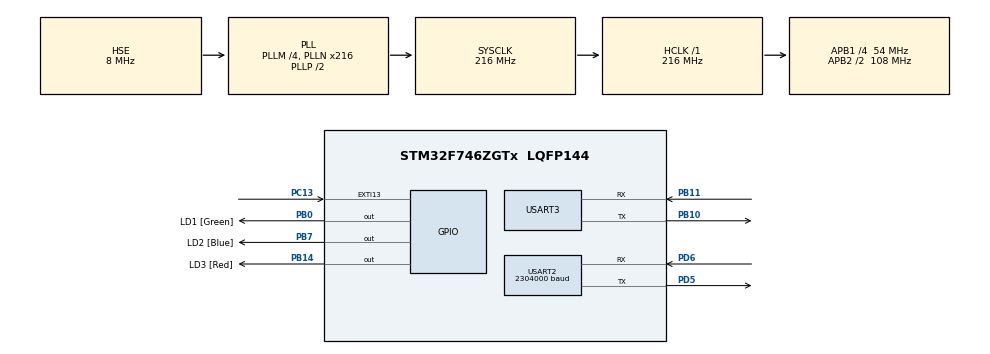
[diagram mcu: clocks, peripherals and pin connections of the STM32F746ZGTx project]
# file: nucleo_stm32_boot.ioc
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CORTEX_M7.ART_ACCLERATOR_ENABLE=1
CORTEX_M7.CPU_DCache=Enabled
CORTEX_M7.CPU_ICache=Enabled
CORTEX_M7.Enable-Cortex_Memory_Protection_Unit_Region0_Settings=MPU_REGION_ENABLE
CORTEX_M7.PREFETCH_ENABLE=1
CORTEX_M7.SubRegionDisable-Cortex_Memory_Protection_Unit_Region0_Settings=0x0
Dma.Request0=USART2_TX
Dma.Request1=USART2_RX
Dma.USART2_RX.1.Direction=DMA_PERIPH_TO_MEMORY
Dma.USART2_RX.1.FIFOMode=DMA_FIFOMODE_DISABLE
Dma.USART2_RX.1.Instance=DMA1_Stream5
Dma.USART2_RX.1.MemDataAlignment=DMA_MDATAALIGN_BYTE
Dma.USART2_RX.1.MemInc=DMA_MINC_ENABLE
Dma.USART2_RX.1.Mode=DMA_CIRCULAR
Dma.USART2_RX.1.PeriphDataAlignment=DMA_PDATAALIGN_BYTE
Dma.USART2_RX.1.PeriphInc=DMA_PINC_DISABLE
Dma.USART2_RX.1.Priority=DMA_PRIORITY_HIGH
Dma.USART2_TX.0.Direction=DMA_MEMORY_TO_PERIPH
Dma.USART2_TX.0.FIFOMode=DMA_FIFOMODE_ENABLE
Dma.USART2_TX.0.FIFOThreshold=DMA_FIFO_THRESHOLD_FULL
Dma.USART2_TX.0.Instance=DMA1_Stream6
Dma.USART2_TX.0.MemBurst=DMA_MBURST_SINGLE
Dma.USART2_TX.0.MemDataAlignment=DMA_MDATAALIGN_BYTE
Dma.USART2_TX.0.MemInc=DMA_MINC_ENABLE
Dma.USART2_TX.0.Mode=DMA_NORMAL
Dma.USART2_TX.0.PeriphBurst=DMA_PBURST_SINGLE
Dma.USART2_TX.0.PeriphDataAlignment=DMA_PDATAALIGN_BYTE
Dma.USART2_TX.0.PeriphInc=DMA_PINC_DISABLE
Dma.USART2_TX.0.Priority=DMA_PRIORITY_VERY_HIGH
Mcu.Family=STM32F7
Mcu.Name=STM32F746ZGTx
Mcu.Package=LQFP144
NVIC.DMA1_Stream5_IRQn=true\:0\:0\:false\:false\:true\:true\:true
NVIC.DMA1_Stream6_IRQn=true\:0\:0\:false\:false\:true\:true\:true
NVIC.EXTI15_10_IRQn=true\:0\:0\:false\:false\:true\:true\:true
NVIC.PriorityGroup=NVIC_PRIORITYGROUP_4
NVIC.USART2_IRQn=true\:0\:0\:false\:false\:true\:true\:true
PA13.GPIO_Label=TMS
PA13.Mode=Serial_Wire
PA13.Signal=SYS_JTMS-SWDIO
PA14.GPIO_Label=TCK
PA14.Mode=Serial_Wire
PA14.Signal=SYS_JTCK-SWCLK
PB0.GPIO_Label=LD1 [Green]
PB0.Signal=GPIO_Output
PB10.Mode=Asynchronous
PB10.Signal=USART3_TX
PB11.Mode=Asynchronous
PB11.Signal=USART3_RX
PB14.GPIO_Label=LD3 [Red]
PB14.Signal=GPIO_Output
PB7.GPIO_Label=LD2 [Blue]
PB7.Signal=GPIO_Output
PC13.Signal=GPXTI13
PC14/OSC32_IN.Mode=LSE-External-Clock-Source
PC14/OSC32_IN.Signal=RCC_OSC32_IN
PC15/OSC32_OUT.Mode=LSE-External-Clock-Source
PC15/OSC32_OUT.Signal=RCC_OSC32_OUT
PD5.Mode=Asynchronous
PD5.Signal=USART2_TX
PD6.GPIO_Speed=GPIO_SPEED_FREQ_VERY_HIGH
PD6.Mode=Asynchronous
PD6.Signal=USART2_RX
PH0/OSC_IN.GPIO_Label=MCO [STM32F103CBT6_PA8]
PH0/OSC_IN.Mode=HSE-External-Clock-Source
PH0/OSC_IN.Signal=RCC_OSC_IN
PH1/OSC_OUT.Mode=HSE-External-Clock-Source
PH1/OSC_OUT.Signal=RCC_OSC_OUT
ProjectManager.HeapSize=0x200
ProjectManager.StackSize=0x400
ProjectManager.TargetToolchain=SW4STM32
RCC.48MHZClocksFreq_Value=24000000
RCC.AHBFreq_Value=216000000
RCC.APB1CLKDivider=RCC_HCLK_DIV4
RCC.APB1Freq_Value=54000000
RCC.APB1TimFreq_Value=108000000
RCC.APB2CLKDivider=RCC_HCLK_DIV2
RCC.APB2Freq_Value=108000000
RCC.APB2TimFreq_Value=216000000
RCC.CortexFreq_Value=216000000
RCC.HCLKFreq_Value=216000000
RCC.HSE_VALUE=8000000
RCC.HSI_VALUE=16000000
RCC.LSE_VALUE=32.768
RCC.PLLM=4
RCC.PLLMUL=RCC_PLL_MUL9
RCC.PLLN=216
RCC.PLLQ=9
RCC.PLLSourceVirtual=RCC_PLLSOURCE_HSE
RCC.PRESCALERUSB=RCC_USBCLKSOURCE_PLL_DIV1_5
RCC.SYSCLKFreq_VALUE=216000000
RCC.SYSCLKSource=RCC_SYSCLKSOURCE_PLLCLK
RCC.SYSCLKSourceVirtual=RCC_SYSCLKSOURCE_PLLCLK
RCC.USBFreq_Value=48000000
RCC.VCOOutputFreq_Value=432000000
USART2.BaudRate=2304000
USART2.VirtualMode-Asynchronous=VM_ASYNC
USART2.WordLength=WORDLENGTH_8B
USART3.VirtualMode-Asynchronous=VM_ASYNC
VP_CRC_VS_CRC.Mode=CRC_Activate
VP_TIM3_VS_ClockSourceINT.Mode=Internal
board=NUCLEO-F746ZG

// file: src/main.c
/* USER CODE BEGIN Header */
/**
  ******************************************************************************
  * @file           : main.c
  * @brief          : Main program body
  ******************************************************************************
  * @attention
  *
  * <h2><center>&copy; Copyright (c) 2019 STMicroelectronics.
  * All rights reserved.</center></h2>
  *
  * This software component is licensed by ST under BSD 3-Clause license,
  * the "License"; You may not use this file except in compliance with the
  * License. You may obtain a copy of the License at:
  *                        opensource.org/licenses/BSD-3-Clause
  *
  ******************************************************************************
  */
/* USER CODE END Header */

#include "main.h"
#include "crc.h"
#include "dma.h"
#include "gfxsimulator.h"
#include "tim.h"
#include "usart.h"
#include "gpio.h"

/* USER CODE BEGIN Includes */
#include <stdio.h>
#include <stdlib.h>

#include "boot_link.h"

#include "download_application.h"
/* USER CODE END Includes */

/* USER CODE BEGIN PV */
/* Private variables ---------------------------------------------------------*/
/* Application start address */

/* USER CODE END PV */

void SystemClock_Config(void);
/* USER CODE BEGIN PFP */
/* Private function prototypes -----------------------------------------------*/
//static void MPU_MyConfig ( void ) ;

/* USER CODE END PFP */

int main(void)
{
  /* USER CODE BEGIN 1 */
	if ( ! applicationDownloadRequested () ) {
		jumpToApplication () ;
	}

  /* USER CODE END 1 */

  /* Enable I-Cache---------------------------------------------------------*/
  SCB_EnableICache();

  /* Enable D-Cache---------------------------------------------------------*/
  SCB_EnableDCache();

  /* MCU Configuration--------------------------------------------------------*/

  /* Reset of all peripherals, Initializes the Flash interface and the Systick. */
  HAL_Init();

  /* Configure the system clock */
  SystemClock_Config();

  /* Initialize all configured peripherals */
  MX_GPIO_Init();
  MX_DMA_Init();
  MX_CRC_Init();
  MX_TIM3_Init();
  MX_USART2_UART_Init();
  MX_GFXSIMULATOR_Init();
  MX_USART3_UART_Init();
  /* USER CODE BEGIN 2 */

	BSP_LED_Init ( LED_GREEN ) ;
	BSP_LED_Init ( LED_BLUE  ) ;
	BSP_LED_Init ( LED_RED 	 ) ;

	if ( otar () == FALSE ) {
		Error_Handler () ;
	}

	NVIC_SystemReset () ;

  /* USER CODE END 2 */

  /* Infinite loop */
	while (1)
	{

	}
}

void SystemClock_Config(void)
{
  RCC_OscInitTypeDef RCC_OscInitStruct = {0};
  RCC_ClkInitTypeDef RCC_ClkInitStruct = {0};
  RCC_PeriphCLKInitTypeDef PeriphClkInitStruct = {0};

  /** Configure the main internal regulator output voltage
  */
  __HAL_RCC_PWR_CLK_ENABLE();
  __HAL_PWR_VOLTAGESCALING_CONFIG(PWR_REGULATOR_VOLTAGE_SCALE1);
  /** Initializes the CPU, AHB and APB busses clocks
  */
  RCC_OscInitStruct.OscillatorType = RCC_OSCILLATORTYPE_HSE;
  RCC_OscInitStruct.HSEState = RCC_HSE_BYPASS;
  RCC_OscInitStruct.PLL.PLLState = RCC_PLL_ON;
  RCC_OscInitStruct.PLL.PLLSource = RCC_PLLSOURCE_HSE;
  RCC_OscInitStruct.PLL.PLLM = 4;
  RCC_OscInitStruct.PLL.PLLN = 216;
  RCC_OscInitStruct.PLL.PLLP = RCC_PLLP_DIV2;
  RCC_OscInitStruct.PLL.PLLQ = 9;
  if (HAL_RCC_OscConfig(&RCC_OscInitStruct) != HAL_OK)
  {
    Error_Handler();
  }
  /** Activate the Over-Drive mode
  */
  if (HAL_PWREx_EnableOverDrive() != HAL_OK)
  {
    Error_Handler();
  }
  /** Initializes the CPU, AHB and APB busses clocks
  */
  RCC_ClkInitStruct.ClockType = RCC_CLOCKTYPE_HCLK|RCC_CLOCKTYPE_SYSCLK
                              |RCC_CLOCKTYPE_PCLK1|RCC_CLOCKTYPE_PCLK2;
  RCC_ClkInitStruct.SYSCLKSource = RCC_SYSCLKSOURCE_PLLCLK;
  RCC_ClkInitStruct.AHBCLKDivider = RCC_SYSCLK_DIV1;
  RCC_ClkInitStruct.APB1CLKDivider = RCC_HCLK_DIV4;
  RCC_ClkInitStruct.APB2CLKDivider = RCC_HCLK_DIV2;

  if (HAL_RCC_ClockConfig(&RCC_ClkInitStruct, FLASH_LATENCY_7) != HAL_OK)
  {
    Error_Handler();
  }
  PeriphClkInitStruct.PeriphClockSelection = RCC_PERIPHCLK_USART2|RCC_PERIPHCLK_USART3;
  PeriphClkInitStruct.Usart2ClockSelection = RCC_USART2CLKSOURCE_PCLK1;
  PeriphClkInitStruct.Usart3ClockSelection = RCC_USART3CLKSOURCE_PCLK1;
  if (HAL_RCCEx_PeriphCLKConfig(&PeriphClkInitStruct) != HAL_OK)
  {
    Error_Handler();
  }
}

void Error_Handler(void)
{
  while(1)
  {
  }
}

/************************ (C) COPYRIGHT STMicroelectronics *****END OF FILE****/
